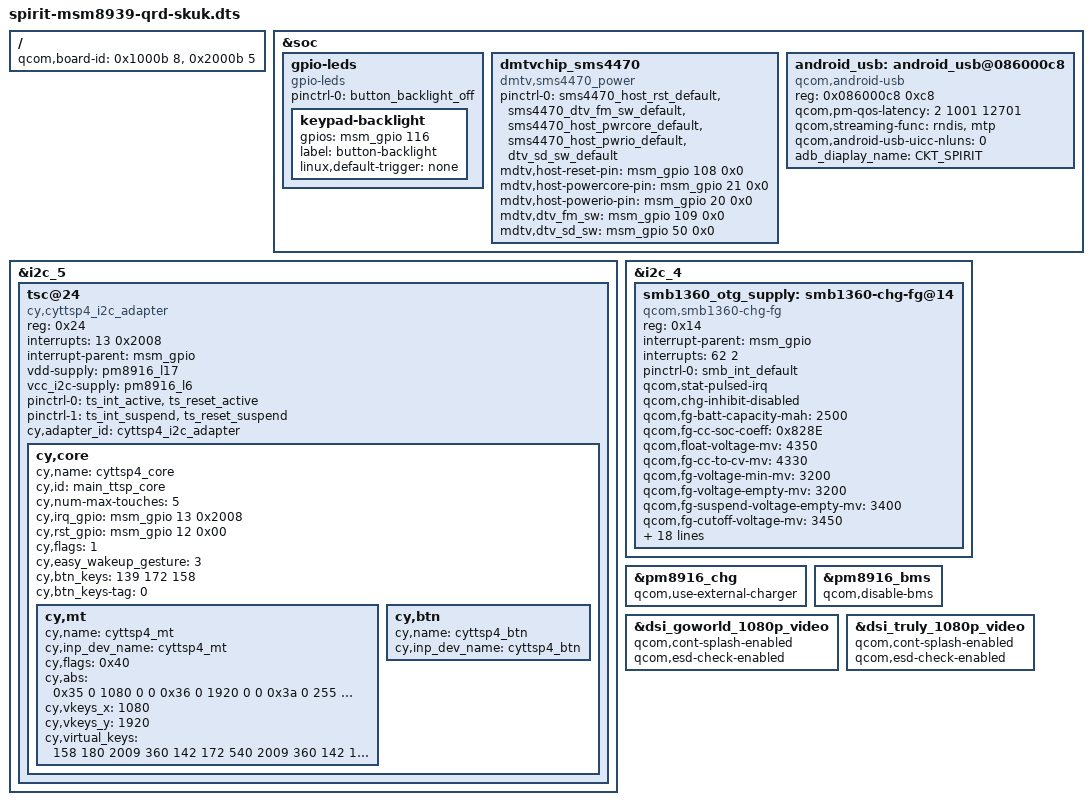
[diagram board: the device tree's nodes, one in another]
/* Copyright (c) 2014, The Linux Foundation. All rights reserved.
 *
 * This program is free software; you can redistribute it and/or modify
 * it under the terms of the GNU General Public License version 2 and
 * only version 2 as published by the Free Software Foundation.
 *
 * This program is distributed in the hope that it will be useful,
 * but WITHOUT ANY WARRANTY; without even the implied warranty of
 * MERCHANTABILITY or FITNESS FOR A PARTICULAR PURPOSE.  See the
 * GNU General Public License for more details.
 */

/dts-v1/;

#include "msm8939.dtsi"
#include "spirit-msm8939-qrd-skuk.dtsi"
#include "dsi-panel-goworld-1080p-video.dtsi"
#include "dsi-panel-truly-1080p-video.dtsi"
#include "spirit-msm8939-camera-sensor-qrd.dtsi"

/ {
	qcom,board-id = <0x1000b 8>, <0x2000b 5>;
};

&soc {
	gpio-leds {
		compatible = "gpio-leds";
		status = "okay";
		pinctrl-names = "default";
		pinctrl-0 = <&button_backlight_off>;

		keypad-backlight {
			gpios = <&msm_gpio 116 0>;
			label = "button-backlight";
			linux,default-trigger = "none";
		};
	};
/*------add for mdtv-sms4470,ck-changjun.li-------*/
	dmtvchip_sms4470{
		compatible = "dmtv,sms4470_power";
		status = "okay";
		pinctrl-names = "default";
		pinctrl-0 = <&sms4470_host_rst_default &sms4470_dtv_fm_sw_default &sms4470_host_pwrcore_default &sms4470_host_pwrio_default &dtv_sd_sw_default>;
		mdtv,host-reset-pin = <&msm_gpio 108 0x0>;
		mdtv,host-powercore-pin = <&msm_gpio 21 0x0>;
		mdtv,host-powerio-pin = <&msm_gpio 20 0x0>;
		mdtv,dtv_fm_sw = <&msm_gpio 109 0x0>;
		mdtv,dtv_sd_sw = <&msm_gpio 50 0x0>;
		//vdd-io-supply = <&pm8916_l12>;//1800000,2950000
		//vdd-emi-supply = <&pm8916_l6>;//1800000,1800000
	};
/*--------------end ck-changjun.li----------------*/

	android_usb: android_usb@086000c8 {
		compatible = "qcom,android-usb";
		reg = <0x086000c8 0xc8>;
		qcom,pm-qos-latency = <2 1001 12701>;
		qcom,streaming-func = "rndis","mtp";
		qcom,android-usb-uicc-nluns = /bits/ 8 <0>;
		adb_diaplay_name = "CKT_SPIRIT";
	};
};

&i2c_5 {
	tsc@24 {
		compatible = "cy,cyttsp4_i2c_adapter";
		reg = <0x24>;
		interrupts = <13 0x2008>;
		interrupt-parent = <&msm_gpio>;
		vdd-supply = <&pm8916_l17>;
		vcc_i2c-supply = <&pm8916_l6>;
		pinctrl-names = "pmx_ts_active","pmx_ts_suspend";
		pinctrl-0 = <&ts_int_active &ts_reset_active>;
		pinctrl-1 = <&ts_int_suspend &ts_reset_suspend>;
		cy,adapter_id = "cyttsp4_i2c_adapter";
		cy,core {
			cy,name = "cyttsp4_core";
			cy,id = "main_ttsp_core";
			cy,num-max-touches = <5>;
			cy,irq_gpio = <&msm_gpio 13 0x2008>;
			cy,rst_gpio = <&msm_gpio 12 0x00>;
			/* Enable cy,max_xfer_len to limit max I2C/SPI transfer length */
			/* cy,max_xfer_len = <0x100>; */

			/* CY_CORE_FLAG_WAKE_ON_GESTURE */
			cy,flags = <1>;

			/* CY_CORE_EWG_TAP_TAP | CY_CORE_EWG_TWO_FINGER_SLIDE */
			cy,easy_wakeup_gesture = <3>;
			cy,btn_keys = <139 /* KEY_MENU */
				172 /* KEY_HOME */
				158>; /* KEY_BACK */
			cy,btn_keys-tag = <0>;
			cy,mt {
				cy,name = "cyttsp4_mt";
				cy,inp_dev_name = "cyttsp4_mt";
				/* CY_MT_FLAG_FLIP | CY_MT_FLAG_INV_X | CY_MT_FLAG_INV_Y */
				cy,flags = <0x40>;
				cy,abs =
					/* ABS_MT_POSITION_X, CY_ABS_MIN_X, CY_ABS_MAX_X, 0, 0 */
					<0x35 0 1080 0 0
					/* ABS_MT_POSITION_Y, CY_ABS_MIN_Y, CY_ABS_MAX_Y, 0, 0 */
					0x36 0 1920 0 0
					/* ABS_MT_PRESSURE, CY_ABS_MIN_P, CY_ABS_MAX_P, 0, 0 */
					0x3a 0 255 0 0
					/* CY_IGNORE_VALUE, CY_ABS_MIN_W, CY_ABS_MAX_W, 0, 0 */
					0xffff 0 255 0 0
					/* ABS_MT_TRACKING_ID, CY_ABS_MIN_T, CY_ABS_MAX_T, 0, 0 */
					0x39 0 15 0 0
					/* ABS_MT_TOUCH_MAJOR, 0, 255, 0, 0 */
					0x30 0 255 0 0
					/* ABS_MT_TOUCH_MINOR, 0, 255, 0, 0 */
					0x31 0 255 0 0
					/* ABS_MT_ORIENTATION, -128, 127, 0, 0 */
					0x34 0xfffffed7 127 0 0>;

				cy,vkeys_x = <1080>;
				cy,vkeys_y = <1920>;
				cy,virtual_keys = /* KeyCode CenterX CenterY Width Height */
					/* KEY_BACK */
					<158 180 2009 360 142
					/* KEY_HOME */
					/*modify the key value of KEY_HOME*/
					172 540 2009 360 142
					/* KEY_MENU */
					139 900 2009 360 142>;
			};
			cy,btn {
				cy,name = "cyttsp4_btn";
				cy,inp_dev_name = "cyttsp4_btn";
			};
		};
	};
};

&i2c_4 {
	smb1360_otg_supply: smb1360-chg-fg@14 {
		compatible = "qcom,smb1360-chg-fg";
		reg = <0x14>;
		interrupt-parent = <&msm_gpio>;
		interrupts = <62 2>;
		pinctrl-names = "default";
		pinctrl-0 = <&smb_int_default>;
		qcom,stat-pulsed-irq;
		qcom,chg-inhibit-disabled;
		/*battery capacity*/
		qcom,fg-batt-capacity-mah = <2500>;
		qcom,fg-cc-soc-coeff = <0x828E>;
		qcom,float-voltage-mv = <4350>;
		qcom,fg-cc-to-cv-mv = <4330>;
		qcom,fg-voltage-min-mv = <3200>;
		qcom,fg-voltage-empty-mv = <3200>;
		qcom,fg-suspend-voltage-empty-mv = <3400>;
		qcom,fg-cutoff-voltage-mv = <3450>;
		//qcom,fg-auto-recharge-soc = <99>;
		qcom,fg-delta-soc = <1>;
		qcom,thermistor-c1-coeff = <0x86C2>;
		qcom,iterm-ma = <200>;
		qcom,recharge-thresh-mv = <100>;
		qcom,charging-timeout = <1536>;
		qcom,otg-batt-curr-limit = <1500>;
		qcom,thermal-mitigation = <1500 1200 900 0>;
		qcom,empty-soc-disabled;
		regulator-name = "smb1360_otg_vreg";
		qcom,fg-reset-at-pon;
		qcom,fg-reset-thresold-mv = <250>;
		qcom,rsense-10mhom;

		qcom,batt-id-disabled;
		/*battery-profile selection properties */
		/*qcom,batt-profile-select;
		qcom,smb1360-vadc = <&pm8916_vadc>;
		qcom,batt-id-vref-uv = <1800000>;
		qcom,batt-id-rpullup-kohm = <100>;
		qcom,profile-a-rid-kohm = <33>;
		qcom,profile-b-rid-kohm = <91>;*/
		qcom,shdn-after-pwroff;
		qcom,config-hard-thresholds;
		qcom,hot-bat-decidegc = <590>;
		qcom,cold-bat-decidegc = <(-200)>;
		qcom,hot-bat-mv = <4100>;
	};
};

&pm8916_chg {
	status = "ok";
	qcom,use-external-charger;
};

&pm8916_bms {
	status = "ok";
	qcom,disable-bms;
};

&dsi_goworld_1080p_video {
	qcom,cont-splash-enabled;
	qcom,esd-check-enabled;
};

&dsi_truly_1080p_video {
	qcom,cont-splash-enabled;
	qcom,esd-check-enabled;
};
